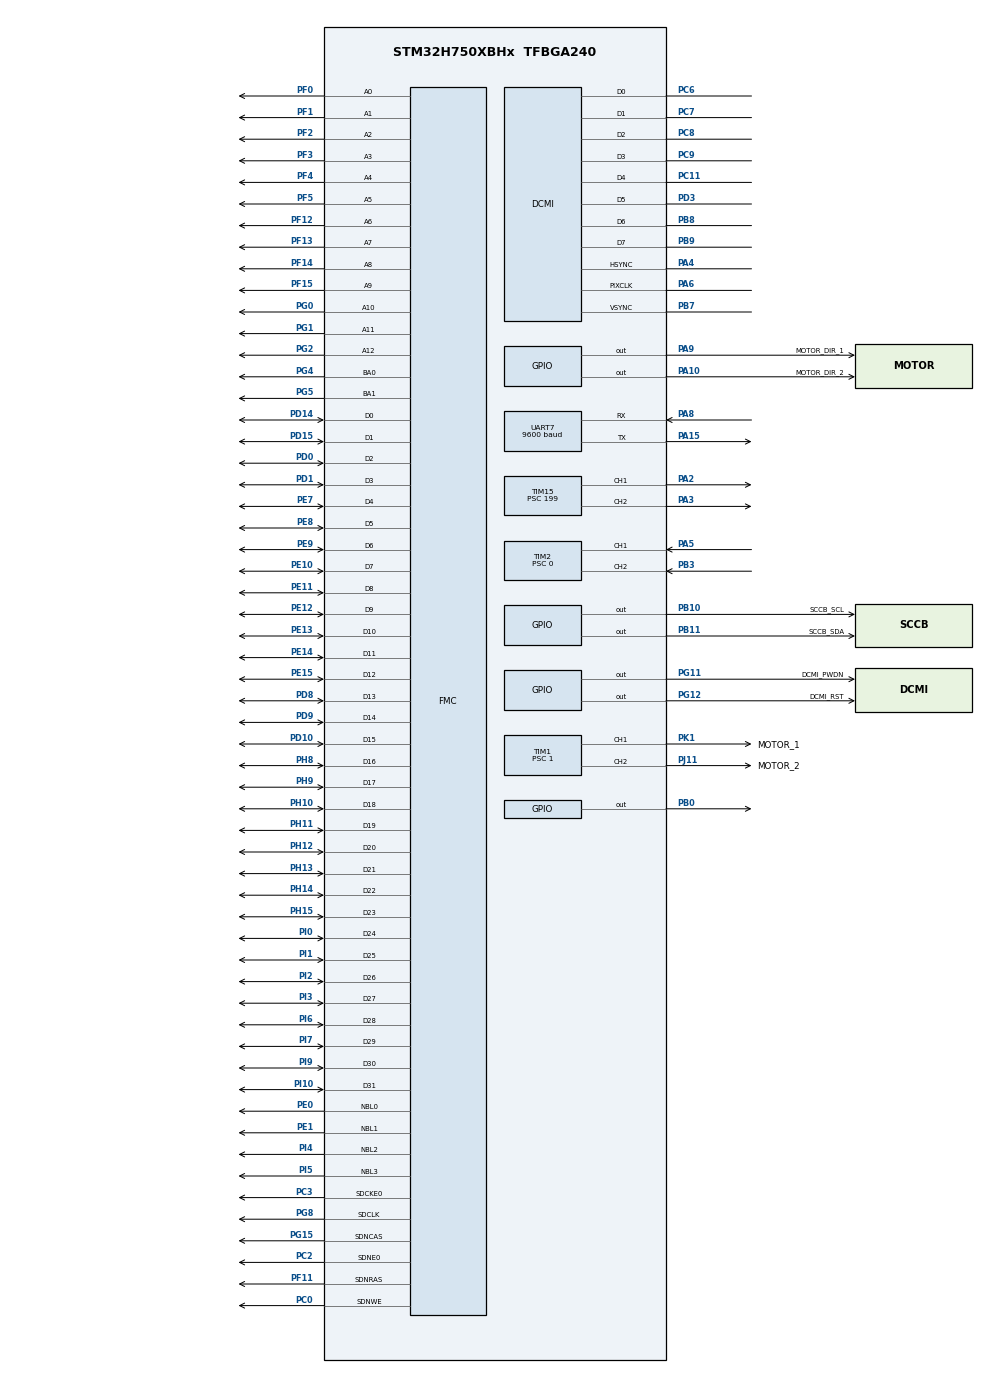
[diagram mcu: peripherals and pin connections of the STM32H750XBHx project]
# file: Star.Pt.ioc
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DCMI.JPEGMode=DCMI_JPEG_ENABLE
DCMI.PCKPolarity=DCMI_PCKPOLARITY_FALLING
Dma.DCMI.0.Direction=DMA_PERIPH_TO_MEMORY
Dma.DCMI.0.EventEnable=DISABLE
Dma.DCMI.0.FIFOMode=DMA_FIFOMODE_ENABLE
Dma.DCMI.0.FIFOThreshold=DMA_FIFO_THRESHOLD_HALFFULL
Dma.DCMI.0.Instance=DMA1_Stream0
Dma.DCMI.0.MemBurst=DMA_MBURST_SINGLE
Dma.DCMI.0.MemDataAlignment=DMA_MDATAALIGN_WORD
Dma.DCMI.0.MemInc=DMA_MINC_ENABLE
Dma.DCMI.0.Mode=DMA_CIRCULAR
Dma.DCMI.0.PeriphBurst=DMA_PBURST_SINGLE
Dma.DCMI.0.PeriphDataAlignment=DMA_PDATAALIGN_WORD
Dma.DCMI.0.PeriphInc=DMA_PINC_DISABLE
Dma.DCMI.0.Polarity=HAL_DMAMUX_REQ_GEN_RISING
Dma.DCMI.0.Priority=DMA_PRIORITY_LOW
Dma.DCMI.0.RequestNumber=1
Dma.DCMI.0.SignalID=NONE
Dma.DCMI.0.SyncEnable=DISABLE
Dma.DCMI.0.SyncPolarity=HAL_DMAMUX_SYNC_NO_EVENT
Dma.DCMI.0.SyncRequestNumber=1
Dma.DCMI.0.SyncSignalID=NONE
Dma.Request0=DCMI
FMC.CASLatency1=FMC_SDRAM_CAS_LATENCY_3
FMC.ColumnBitsNumber1=FMC_SDRAM_COLUMN_BITS_NUM_9
FMC.ExitSelfRefreshDelay1=8
FMC.LoadToActiveDelay1=2
FMC.RCDDelay1=6
FMC.RPDelay1=2
FMC.RPDelay2=2
FMC.ReadBurst1=FMC_SDRAM_RBURST_ENABLE
FMC.ReadBurst2=FMC_SDRAM_RBURST_ENABLE
FMC.ReadPipeDelay1=FMC_SDRAM_RPIPE_DELAY_0
FMC.RowCycleDelay1=6
FMC.RowCycleDelay2=6
FMC.SDClockPeriod1=FMC_SDRAM_CLOCK_PERIOD_2
FMC.SDClockPeriod2=FMC_SDRAM_CLOCK_PERIOD_2
FMC.SelfRefreshTime1=6
FMC.WriteRecoveryTime1=2
Mcu.Family=STM32H7
Mcu.Name=STM32H750XBHx
Mcu.Package=TFBGA240
NVIC.DCMI_IRQn=true\:0\:0\:false\:false\:true\:true\:true
NVIC.DMA1_Stream0_IRQn=true\:0\:0\:false\:false\:true\:false\:true
NVIC.PriorityGroup=NVIC_PRIORITYGROUP_2
NVIC.TIM16_IRQn=true\:2\:2\:true\:false\:true\:true\:true
NVIC.TIM17_IRQn=true\:2\:1\:true\:false\:true\:true\:true
NVIC.UART7_IRQn=true\:3\:3\:true\:false\:true\:true\:true
PA10.GPIO_Label=MOTOR_DIR_2
PA10.Signal=GPIO_Output
PA13\ (JTMS/SWDIO).Mode=Serial_Wire
PA13\ (JTMS/SWDIO).Signal=DEBUG_JTMS-SWDIO
PA14\ (JTCK/SWCLK).Mode=Serial_Wire
PA14\ (JTCK/SWCLK).Signal=DEBUG_JTCK-SWCLK
PA15\ (JTDI).Mode=Asynchronous
PA15\ (JTDI).Signal=UART7_TX
PA2.Signal=S_TIM15_CH1
PA3.Signal=S_TIM15_CH2
PA4.Mode=Slave_8_bits_External_Synchro
PA4.Signal=DCMI_HSYNC
PA5.GPIO_Speed=GPIO_SPEED_FREQ_VERY_HIGH
PA5.Signal=S_TIM2_CH1
PA6.Mode=Slave_8_bits_External_Synchro
PA6.Signal=DCMI_PIXCLK
PA8.Mode=Asynchronous
PA8.Signal=UART7_RX
PA9.GPIO_Label=MOTOR_DIR_1
PA9.Signal=GPIO_Output
PB0.Signal=GPIO_Output
PB10.GPIO_Label=SCCB_SCL
PB10.GPIO_PuPd=GPIO_PULLUP
PB10.GPIO_Speed=GPIO_SPEED_FREQ_VERY_HIGH
PB10.Signal=GPIO_Output
PB11.GPIO_Label=SCCB_SDA
PB11.GPIO_PuPd=GPIO_PULLUP
PB11.GPIO_Speed=GPIO_SPEED_FREQ_VERY_HIGH
PB11.Signal=GPIO_Output
PB3\ (JTDO/TRACESWO).GPIO_Speed=GPIO_SPEED_FREQ_VERY_HIGH
PB3\ (JTDO/TRACESWO).Signal=S_TIM2_CH2
PB7.Mode=Slave_8_bits_External_Synchro
PB7.Signal=DCMI_VSYNC
PB8.Mode=Slave_8_bits_External_Synchro
PB8.Signal=DCMI_D6
PB9.Mode=Slave_8_bits_External_Synchro
PB9.Signal=DCMI_D7
PC0.Signal=FMC_SDNWE
PC11.Mode=Slave_8_bits_External_Synchro
PC11.Signal=DCMI_D4
PC14-OSC32_IN\ (OSC32_IN).Mode=LSE-External-Oscillator
PC14-OSC32_IN\ (OSC32_IN).Signal=RCC_OSC32_IN
PC15-OSC32_OUT\ (OSC32_OUT).Mode=LSE-External-Oscillator
PC15-OSC32_OUT\ (OSC32_OUT).Signal=RCC_OSC32_OUT
PC2.Mode=SdramChipSelect1_1
PC2.Signal=FMC_SDNE0
PC3.Mode=SdramChipSelect1_1
PC3.Signal=FMC_SDCKE0
PC6.Mode=Slave_8_bits_External_Synchro
PC6.Signal=DCMI_D0
PC7.Mode=Slave_8_bits_External_Synchro
PC7.Signal=DCMI_D1
PC8.Mode=Slave_8_bits_External_Synchro
PC8.Signal=DCMI_D2
PC9.Mode=Slave_8_bits_External_Synchro
PC9.Signal=DCMI_D3
PD0.Signal=FMC_D2_DA2
PD1.Signal=FMC_D3_DA3
PD10.Signal=FMC_D15_DA15
PD14.Signal=FMC_D0_DA0
PD15.Signal=FMC_D1_DA1
PD3.Mode=Slave_8_bits_External_Synchro
PD3.Signal=DCMI_D5
PD8.Signal=FMC_D13_DA13
PD9.Signal=FMC_D14_DA14
PE0.Signal=FMC_NBL0
PE1.Signal=FMC_NBL1
PE10.Signal=FMC_D7_DA7
PE11.Signal=FMC_D8_DA8
PE12.Signal=FMC_D9_DA9
PE13.Signal=FMC_D10_DA10
PE14.Signal=FMC_D11_DA11
PE15.Signal=FMC_D12_DA12
PE7.Signal=FMC_D4_DA4
PE8.Signal=FMC_D5_DA5
PE9.Signal=FMC_D6_DA6
PF0.Signal=FMC_A0
PF1.Signal=FMC_A1
PF11.Signal=FMC_SDNRAS
PF12.Signal=FMC_A6
PF13.Signal=FMC_A7
PF14.Signal=FMC_A8
PF15.Signal=FMC_A9
PF2.Signal=FMC_A2
PF3.Signal=FMC_A3
PF4.Signal=FMC_A4
PF5.Signal=FMC_A5
PG0.Signal=FMC_A10
PG1.Signal=FMC_A11
PG11.GPIO_Label=DCMI_PWDN
PG11.Signal=GPIO_Output
PG12.GPIO_Label=DCMI_RST
PG12.Signal=GPIO_Output
PG15.Signal=FMC_SDNCAS
PG2.Signal=FMC_A12
PG4.Signal=FMC_A14_BA0
PG5.Signal=FMC_A15_BA1
PG8.Signal=FMC_SDCLK
PH0-OSC_IN\ (PH0).Mode=HSE-External-Oscillator
PH0-OSC_IN\ (PH0).Signal=RCC_OSC_IN
PH1-OSC_OUT\ (PH1).Mode=HSE-External-Oscillator
PH1-OSC_OUT\ (PH1).Signal=RCC_OSC_OUT
PH10.Signal=FMC_D18
PH11.Signal=FMC_D19
PH12.Signal=FMC_D20
PH13.Signal=FMC_D21
PH14.Signal=FMC_D22
PH15.Signal=FMC_D23
PH8.Signal=FMC_D16
PH9.Signal=FMC_D17
PI0.Signal=FMC_D24
PI1.Signal=FMC_D25
PI10.Signal=FMC_D31
PI2.Signal=FMC_D26
PI3.Signal=FMC_D27
PI4.Signal=FMC_NBL2
PI5.Signal=FMC_NBL3
PI6.Signal=FMC_D28
PI7.Signal=FMC_D29
PI9.Signal=FMC_D30
PJ11.GPIO_Label=MOTOR_2
PJ11.Signal=S_TIM1_CH2
PK1.GPIO_Label=MOTOR_1
PK1.Signal=S_TIM1_CH1
ProjectManager.HeapSize=0x200
ProjectManager.StackSize=0x400
ProjectManager.TargetToolchain=MDK-ARM V5.27
RCC.ADCFreq_Value=50390625
RCC.APB1Freq_Value=100000000
RCC.APB2Freq_Value=100000000
RCC.APB3Freq_Value=100000000
RCC.APB4Freq_Value=100000000
RCC.CortexFreq_Value=400000000
RCC.D1PPRE=RCC_APB3_DIV2
RCC.D2PPRE1=RCC_APB1_DIV2
RCC.D2PPRE2=RCC_APB2_DIV2
RCC.D3PPRE=RCC_APB4_DIV2
RCC.DIVM1=2
RCC.DIVN1=64
RCC.HCLKFreq_Value=200000000
RCC.HPRE=RCC_HCLK_DIV2
RCC.LockedElements=FMCoutput,Tim2Output
RCC.PLLFRACN=0
RCC.PLLSourceVirtual=RCC_PLLSOURCE_HSE
RCC.PWR_Regulator_Voltage_Scale=PWR_REGULATOR_VOLTAGE_SCALE0
RCC.SYSCLKFreq_VALUE=400000000
RCC.SYSCLKSource=RCC_SYSCLKSOURCE_PLLCLK
RCC.USBFreq_Value=400000000
SH.FMC_A0.0=FMC_A0,13b-sda1
SH.FMC_A1.0=FMC_A1,13b-sda1
SH.FMC_A10.0=FMC_A10,13b-sda1
SH.FMC_A11.0=FMC_A11,13b-sda1
SH.FMC_A12.0=FMC_A12,13b-sda1
SH.FMC_A14_BA0.0=FMC_BA0,FourSdramBanks1
SH.FMC_A15_BA1.0=FMC_BA1,FourSdramBanks1
SH.FMC_A2.0=FMC_A2,13b-sda1
SH.FMC_A3.0=FMC_A3,13b-sda1
SH.FMC_A4.0=FMC_A4,13b-sda1
SH.FMC_A5.0=FMC_A5,13b-sda1
SH.FMC_A6.0=FMC_A6,13b-sda1
SH.FMC_A7.0=FMC_A7,13b-sda1
SH.FMC_A8.0=FMC_A8,13b-sda1
SH.FMC_A9.0=FMC_A9,13b-sda1
SH.FMC_D0_DA0.0=FMC_D0,sd-32b-d1
SH.FMC_D10_DA10.0=FMC_D10,sd-32b-d1
SH.FMC_D11_DA11.0=FMC_D11,sd-32b-d1
SH.FMC_D12_DA12.0=FMC_D12,sd-32b-d1
SH.FMC_D13_DA13.0=FMC_D13,sd-32b-d1
SH.FMC_D14_DA14.0=FMC_D14,sd-32b-d1
SH.FMC_D15_DA15.0=FMC_D15,sd-32b-d1
SH.FMC_D16.0=FMC_D16,sd-32b-d1
SH.FMC_D17.0=FMC_D17,sd-32b-d1
SH.FMC_D18.0=FMC_D18,sd-32b-d1
SH.FMC_D19.0=FMC_D19,sd-32b-d1
SH.FMC_D1_DA1.0=FMC_D1,sd-32b-d1
SH.FMC_D20.0=FMC_D20,sd-32b-d1
SH.FMC_D21.0=FMC_D21,sd-32b-d1
SH.FMC_D22.0=FMC_D22,sd-32b-d1
SH.FMC_D23.0=FMC_D23,sd-32b-d1
SH.FMC_D24.0=FMC_D24,sd-32b-d1
SH.FMC_D25.0=FMC_D25,sd-32b-d1
SH.FMC_D26.0=FMC_D26,sd-32b-d1
SH.FMC_D27.0=FMC_D27,sd-32b-d1
SH.FMC_D28.0=FMC_D28,sd-32b-d1
SH.FMC_D29.0=FMC_D29,sd-32b-d1
SH.FMC_D2_DA2.0=FMC_D2,sd-32b-d1
SH.FMC_D30.0=FMC_D30,sd-32b-d1
SH.FMC_D31.0=FMC_D31,sd-32b-d1
SH.FMC_D3_DA3.0=FMC_D3,sd-32b-d1
SH.FMC_D4_DA4.0=FMC_D4,sd-32b-d1
SH.FMC_D5_DA5.0=FMC_D5,sd-32b-d1
SH.FMC_D6_DA6.0=FMC_D6,sd-32b-d1
SH.FMC_D7_DA7.0=FMC_D7,sd-32b-d1
SH.FMC_D8_DA8.0=FMC_D8,sd-32b-d1
SH.FMC_D9_DA9.0=FMC_D9,sd-32b-d1
SH.FMC_NBL0.0=FMC_NBL0,Sd4ByteEnable1
SH.FMC_NBL1.0=FMC_NBL1,Sd4ByteEnable1
SH.FMC_NBL2.0=FMC_NBL2,Sd4ByteEnable1
SH.FMC_NBL3.0=FMC_NBL3,Sd4ByteEnable1
SH.FMC_SDCLK.0=FMC_SDCLK,13b-sda1
SH.FMC_SDNCAS.0=FMC_SDNCAS,13b-sda1
SH.FMC_SDNRAS.0=FMC_SDNRAS,13b-sda1
SH.FMC_SDNWE.0=FMC_SDNWE,13b-sda1
SH.S_TIM15_CH1.0=TIM15_CH1,PWM Generation1 CH1
SH.S_TIM15_CH2.0=TIM15_CH2,PWM Generation2 CH2
SH.S_TIM1_CH1.0=TIM1_CH1,PWM Generation1 CH1
SH.S_TIM1_CH2.0=TIM1_CH2,PWM Generation2 CH2
SH.S_TIM2_CH1.0=TIM2_CH1,Encoder_Interface
SH.S_TIM2_CH2.0=TIM2_CH2,Encoder_Interface
TIM1.AutoReloadPreload=TIM_AUTORELOAD_PRELOAD_ENABLE
TIM1.Channel-PWM\ Generation1\ CH1=TIM_CHANNEL_1
TIM1.Channel-PWM\ Generation2\ CH2=TIM_CHANNEL_2
TIM1.Period=999
TIM1.Prescaler=1
TIM15.Channel-PWM\ Generation1\ CH1=TIM_CHANNEL_1
TIM15.Channel-PWM\ Generation2\ CH2=TIM_CHANNEL_2
TIM15.Period=19999
TIM15.Prescaler=199
TIM15.Pulse-PWM\ Generation1\ CH1=1500
TIM15.Pulse-PWM\ Generation2\ CH2=1500
TIM16.AutoReloadPreload=TIM_AUTORELOAD_PRELOAD_ENABLE
TIM16.Period=99
TIM16.Prescaler=199
TIM17.AutoReloadPreload=TIM_AUTORELOAD_PRELOAD_ENABLE
TIM17.Period=99
TIM17.Prescaler=199
TIM2.AutoReloadPreload=TIM_AUTORELOAD_PRELOAD_ENABLE
TIM2.EncoderMode=TIM_ENCODERMODE_TI12
TIM2.Prescaler=0
UART7.BaudRate=9600
VP_TIM15_VS_ClockSourceINT.Mode=Internal
VP_TIM16_VS_ClockSourceINT.Mode=Enable_Timer
VP_TIM17_VS_ClockSourceINT.Mode=Enable_Timer
VP_TIM1_VS_ClockSourceINT.Mode=Internal
board=custom

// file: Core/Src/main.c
/* USER CODE BEGIN Header */
/**
  ******************************************************************************
  * @file           : main.c
  * @brief          : Main program body
  ******************************************************************************
  * @attention
  *
  * <h2><center>&copy; Copyright (c) 2021 STMicroelectronics.
  * All rights reserved.</center></h2>
  *
  * This software component is licensed by ST under BSD 3-Clause license,
  * the "License"; You may not use this file except in compliance with the
  * License. You may obtain a copy of the License at:
  *                        opensource.org/licenses/BSD-3-Clause
  *
  ******************************************************************************
  */
/*----------ATTENTION-----------
@ Use MicroLib!S
------------------------------*/
/* USER CODE END Header */
#include "main.h"
#include "dcmi.h"
#include "dma.h"
#include "tim.h"
#include "usart.h"
#include "gpio.h"
#include "fmc.h"

/* USER CODE BEGIN Includes */
#include "usmart.h"
#include "camera.h"

#include "user_motor_init.h"
/* USER CODE END Includes */

void SystemClock_Config(void);

int main(void)
{

  /* MCU Configuration--------------------------------------------------------*/

  /* Reset of all peripherals, Initializes the Flash interface and the Systick. */
  HAL_Init();

  /* Configure the system clock */
  SystemClock_Config();

  /* Initialize all configured peripherals */
  MX_GPIO_Init();
  MX_DMA_Init();
  MX_FMC_Init();
  MX_TIM16_Init();
  MX_DCMI_Init();
  MX_TIM1_Init();
  MX_UART7_Init();
  MX_TIM2_Init();
  MX_TIM17_Init();
  MX_TIM15_Init();
  /* USER CODE BEGIN 2 */
  //I2C->CAMERA->DCMI?
  //CAMERA_Init();
  Motor_Init();

  //HAL_GPIO_WritePin(GPIOB,GPIO_PIN_0,GPIO_PIN_RESET);
  /* USER CODE END 2 */

  /* Infinite loop */
  while (1)
  {

    /* USER CODE BEGIN 3 */
	 HAL_Delay(1000);
	HAL_GPIO_TogglePin(GPIOB,GPIO_PIN_0);
  }
  /* USER CODE END 3 */
}

void SystemClock_Config(void)
{
  RCC_OscInitTypeDef RCC_OscInitStruct = {0};
  RCC_ClkInitTypeDef RCC_ClkInitStruct = {0};

  /** Supply configuration update enable
  */
  HAL_PWREx_ConfigSupply(PWR_LDO_SUPPLY);
  /** Configure the main internal regulator output voltage
  */
  __HAL_PWR_VOLTAGESCALING_CONFIG(PWR_REGULATOR_VOLTAGE_SCALE0);

  while(!__HAL_PWR_GET_FLAG(PWR_FLAG_VOSRDY)) {}
  /** Initializes the RCC Oscillators according to the specified parameters
  * in the RCC_OscInitTypeDef structure.
  */
  RCC_OscInitStruct.OscillatorType = RCC_OSCILLATORTYPE_HSE;
  RCC_OscInitStruct.HSEState = RCC_HSE_ON;
  RCC_OscInitStruct.PLL.PLLState = RCC_PLL_ON;
  RCC_OscInitStruct.PLL.PLLSource = RCC_PLLSOURCE_HSE;
  RCC_OscInitStruct.PLL.PLLM = 2;
  RCC_OscInitStruct.PLL.PLLN = 64;
  RCC_OscInitStruct.PLL.PLLP = 2;
  RCC_OscInitStruct.PLL.PLLQ = 2;
  RCC_OscInitStruct.PLL.PLLR = 2;
  RCC_OscInitStruct.PLL.PLLRGE = RCC_PLL1VCIRANGE_3;
  RCC_OscInitStruct.PLL.PLLVCOSEL = RCC_PLL1VCOWIDE;
  RCC_OscInitStruct.PLL.PLLFRACN = 0;
  if (HAL_RCC_OscConfig(&RCC_OscInitStruct) != HAL_OK)
  {
    Error_Handler();
  }
  /** Initializes the CPU, AHB and APB buses clocks
  */
  RCC_ClkInitStruct.ClockType = RCC_CLOCKTYPE_HCLK|RCC_CLOCKTYPE_SYSCLK
                              |RCC_CLOCKTYPE_PCLK1|RCC_CLOCKTYPE_PCLK2
                              |RCC_CLOCKTYPE_D3PCLK1|RCC_CLOCKTYPE_D1PCLK1;
  RCC_ClkInitStruct.SYSCLKSource = RCC_SYSCLKSOURCE_PLLCLK;
  RCC_ClkInitStruct.SYSCLKDivider = RCC_SYSCLK_DIV1;
  RCC_ClkInitStruct.AHBCLKDivider = RCC_HCLK_DIV2;
  RCC_ClkInitStruct.APB3CLKDivider = RCC_APB3_DIV2;
  RCC_ClkInitStruct.APB1CLKDivider = RCC_APB1_DIV2;
  RCC_ClkInitStruct.APB2CLKDivider = RCC_APB2_DIV2;
  RCC_ClkInitStruct.APB4CLKDivider = RCC_APB4_DIV2;

  if (HAL_RCC_ClockConfig(&RCC_ClkInitStruct, FLASH_LATENCY_2) != HAL_OK)
  {
    Error_Handler();
  }
}

void Error_Handler(void)
{
  __disable_irq();
  while (1)
  {
  }
}

/************************ (C) COPYRIGHT STMicroelectronics *****END OF FILE****/
